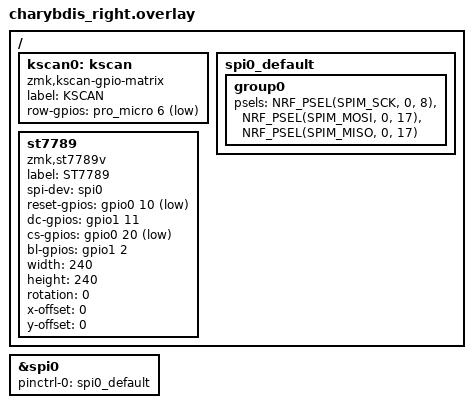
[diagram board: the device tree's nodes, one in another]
/*
 * ST7789 显示屏驱动配置文件
 * 格式参考：gc9a01a 驱动，适用于 ZMK 固件
 *
 * 适用于 Zephyr pinctrl 方式配置的 ZMK 版本
 *
 * 引脚说明（按需修改）：
 *   SCK   → gpio0 pin 8
 *   MOSI  → gpio0 pin 17
 *   MISO  → gpio0 pin 17  (通常 ST7789 只需 MOSI，MISO 可与 MOSI 同脚或悬空)
 *   RST   → gpio0 pin 10
 *   DC    → gpio1 pin 11
 *   CS    → gpio0 pin 20
 *   BL    → gpio1 pin 2
 *
 * ST7789 常见分辨率：
 *   240x240 (方屏)  x-offset=0  y-offset=0
 *   240x320 (竖屏)  x-offset=0  y-offset=0
 *   170x320 (T-Display-S3 等)  x-offset=35 y-offset=0
 *   240x135 (T-Display 等)     x-offset=40 y-offset=53
 */

#include "charybdis.dtsi"
#include <dt-bindings/gpio/gpio.h>
#include <dt-bindings/pinctrl/nrf-pinctrl.h>

/ {
    kscan0: kscan {
        compatible = "zmk,kscan-gpio-matrix";
        label = "KSCAN";
        row-gpios = <&pro_micro 6 (GPIO_ACTIVE_LOW | GPIO_PULL_UP)>;
    };
};

/ {
    /* -------------------------------------------------------
     * SPI pinctrl 配置（Zephyr 统一引脚管理方式）
     *
     * 格式说明：
     *   <PSEL|pin_num  & 0xFF>  即 <引脚号>
     *   ST7789 只写屏，MISO 通常设为 NOT_CONNECTED
     *   如果不想用硬件 CS（显示屏用软件 CS），可在 spim 中不定义 cs-pin
     * ------------------------------------------------------- */
    spi0_default: spi0_default {
        group0 {
            psels = <NRF_PSEL(SPIM_SCK, 0, 8)>,
                    <NRF_PSEL(SPIM_MOSI, 0, 17)>,
                    <NRF_PSEL(SPIM_MISO, 0, 17)>;
        };
    };

    /* -------------------------------------------------------
     * ST7789 显示屏节点定义
     *
     * compatible 字段需要 ZMK 源码中存在对应驱动：
     *   zmk,st7789v  ← 推荐，ZMK 官方/社区驱动标识
     *
     * 若你的 ZMK 版本使用不同标识，可替换为：
     *   "sitronix,st7789v"  (Zephyr 上游标识)
     * ------------------------------------------------------- */
    st7789: st7789 {
        compatible = "zmk,st7789v";
        label = "ST7789";

        /* SPI 总线绑定 */
        spi-dev = <&spi0>;

        /* 控制引脚（根据实际接线修改） */
        reset-gpios = <&gpio0 10 (GPIO_ACTIVE_LOW)>;   /* RST，低电平复位 */
        dc-gpios    = <&gpio1 11 (GPIO_ACTIVE_HIGH)>;  /* D/C，高=数据 低=命令 */
        cs-gpios    = <&gpio0 20 (GPIO_ACTIVE_LOW)>;   /* CS，低电平选中 */
        bl-gpios    = <&gpio1  2 (GPIO_ACTIVE_HIGH)>;  /* 背光，高电平点亮；如无背光可删除 */

        /* 屏幕参数 —— 根据你的模组型号选择 */
        width    = <240>;  /* 像素宽度 */
        height   = <240>;  /* 像素高度 */
        rotation = <0>;    /* 旋转角度：0 / 90 / 180 / 270 */
        x-offset = <0>;    /* 列偏移（240x240 方屏填 0） */
        y-offset = <0>;    /* 行偏移（240x240 方屏填 0） */

        /*
         * 常见偏移量参考（ST7789 内部 RAM 为 240x320，小尺寸屏需偏移）：
         *   240x240  →  x-offset=0,  y-offset=0
         *   240x135  →  x-offset=40, y-offset=53
         *   170x320  →  x-offset=35, y-offset=0
         *   135x240  →  x-offset=52, y-offset=40  (横屏 240x135)
         */
    };
};

/* -------------------------------------------------------
 * SPI 总线配置 —— 使用 pinctrl 方式（新版 Zephyr 必须）
 * ------------------------------------------------------- */
&spi0 {
    status = "okay";

    /* 引脚必须通过 pinctrl-0 配置，不再支持 sck-pin/mosi-pin 写法 */
    pinctrl-0 = <&spi0_default>;
    pinctrl-names = "default";

    /*
     * 注意：cs-pin 不在此处定义
     * 显示屏的 CS 由屏幕节点通过 cs-gpios 单独控制
     * 如果 spi0 本身需要片选（如接其他 SPI 设备），可加：
     *   cs-gpios = <&gpioX Y GPIO_ACTIVE_LOW>;
     */
};
